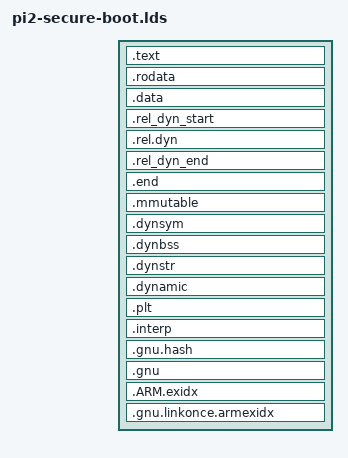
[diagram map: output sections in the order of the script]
OUTPUT_FORMAT("elf32-littlearm", "elf32-littlearm", "elf32-littlearm")
OUTPUT_ARCH(arm)
ENTRY(_start)
SECTIONS
{
 . = 0x00000000;
 . = ALIGN(4);
 .text :
 {
  *(.text*)
 }
 . = ALIGN(4);
 .rodata : { *(SORT_BY_ALIGNMENT(SORT_BY_NAME(.rodata*))) }
 . = ALIGN(4);
 .data : {
  *(.data*)
 }
 . = ALIGN(4);
 . = .;
 .rel_dyn_start :
 {
  *(.__rel_dyn_start)
 }
 .rel.dyn : {
  *(.rel*)
 }
 .rel_dyn_end :
 {
  *(.__rel_dyn_end)
 }
 .end :
 {
  *(.__end)
 }
 _image_binary_end = .;
 . = ALIGN(4096);
 .mmutable : {
  *(.mmutable)
 }
 .dynsym _image_binary_end : { *(.dynsym) }
 .dynbss : { *(.dynbss) }
 .dynstr : { *(.dynstr*) }
 .dynamic : { *(.dynamic*) }
 .plt : { *(.plt*) }
 .interp : { *(.interp*) }
 .gnu.hash : { *(.gnu.hash) }
 .gnu : { *(.gnu*) }
 .ARM.exidx : { *(.ARM.exidx*) }
 .gnu.linkonce.armexidx : { *(.gnu.linkonce.armexidx.*) }
}

